# STM32L412xx register map
File version: 1.0
Registers are 32-bit, read-write, reset 0x0 unless marked. A register's access mark holds for its fields unless they carry their own. Offsets are from the block's base; [hi:lo] are bit positions; {n}, {i} and the like mark numbered series; 'fields as' and 'values as' point back to an identical list.

## FIREWALL
Base 0x40011C00
0x00 CSSA — Code Segment Start Address register
0x04 CSL — Code Segment Length register
0x08 NVDSSA — NON volatile data Segment Start Address register
0x0C NVDSL — NON volatile data Segment Length register
0x10 VDSSA — Volatile data Segment Start Address register
0x14 VDSL — Volatile data Segment Length register
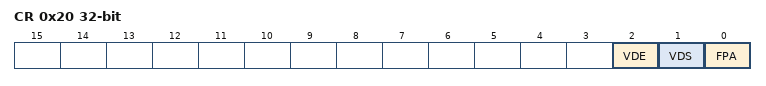
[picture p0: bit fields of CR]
0x20 CR — Configuration register
  [2] VDE — Volatile Data Execution
  [1] VDS — Volatile Data Sharing
  [0] FPA — Firewall Pre Arm

## DMA1
Base 0x40020000
Same registers: DMA2 0x40020400
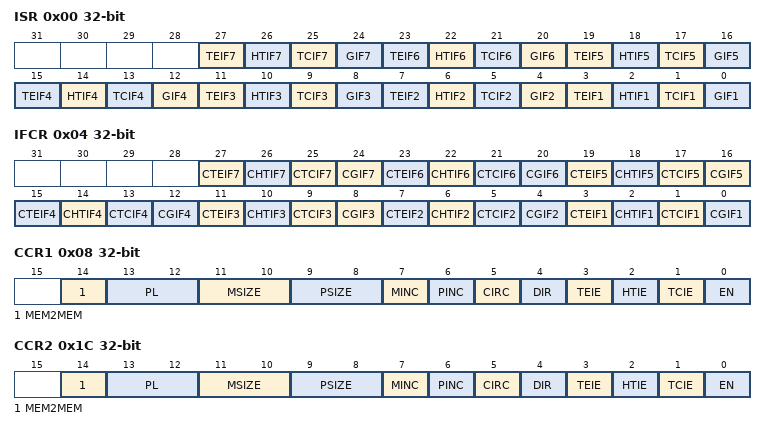
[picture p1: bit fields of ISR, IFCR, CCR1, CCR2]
0x00 ISR — DMA interrupt status register
  [4n-1] TEIF{n} (n=1..7) — Channel {n} Transfer Error flag
  [4n-2] HTIF{n} (n=1..7) — Channel {n} Half Transfer flag
  [4n-3] TCIF{n} (n=1..7) — Channel {n} Transfer Complete flag
  [4n-4] GIF{n} (n=1..7) — Channel {n} Global interrupt flag
0x04 IFCR — DMA interrupt flag clear register
  [4n-1] CTEIF{n} (n=1..7) — Channel {n} Transfer Error clear
  [4n-2] CHTIF{n} (n=1..7) — Channel {n} Half Transfer clear
  [4n-3] CTCIF{n} (n=1..7) — Channel {n} Transfer Complete clear
  [4n-4] CGIF{n} (n=2..7) — Channel {n} Global interrupt clear
  [0] CGIF1 — Channel 1 Global interrupt clearr
0x08 CCR1 — DMA channel x configuration register
  [14] MEM2MEM — Memory to memory mode
  [13:12] PL — PL[1:0] bits(Channel Priority level)
  [11:10] MSIZE — MSIZE[1:0] bits (Memory size)
  [9:8] PSIZE — PSIZE[1:0] bits (Peripheral size)
  [7] MINC — Memory increment mode
  [6] PINC — Peripheral increment mode
  [5] CIRC — Circular mode
  [4] DIR — Data transfer direction
  [3] TEIE — Transfer error interrupt enable
  [2] HTIE — Half Transfer interrupt enable
  [1] TCIE — Transfer complete interrupt enable
  [0] EN — Channel enable
0x0C CNDTR1 — DMA channel x number of data register
  [15:0] NDT — Number of data to Transfer
0x10 CPAR1 — DMA channel x peripheral address register
  [31:0] PA — Peripheral Address
{0x0+0x14*i} CMAR{i} (i=1..7) — DMA channel x memory address register
  [31:0] MA — Memory Address
0x1C CCR2 — DMA channel x configuration register
  fields as CCR1
0x20 CNDTR2 — DMA channel x number of data register
  [15:0] NDT — Number of data to Transfer
0x24 CPAR2 — DMA channel x peripheral address register
  [31:0] PA — Peripheral Address
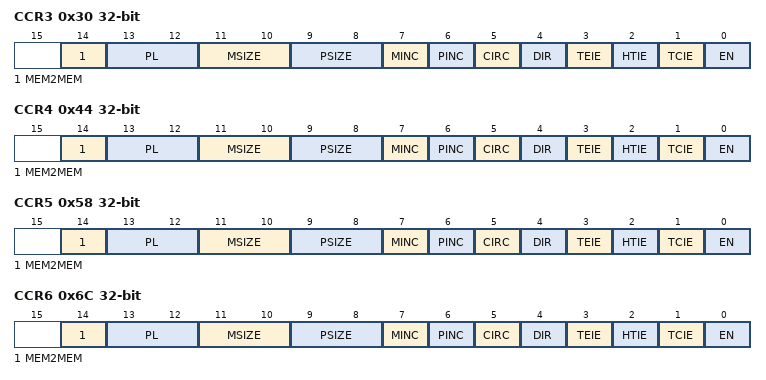
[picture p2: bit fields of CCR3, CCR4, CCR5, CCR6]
0x30 CCR3 — DMA channel x configuration register
  fields as CCR1
0x34 CNDTR3 — DMA channel x number of data register
  [15:0] NDT — Number of data to Transfer
0x38 CPAR3 — DMA channel x peripheral address register
  [31:0] PA — Peripheral Address
0x44 CCR4 — DMA channel x configuration register
  fields as CCR1
0x48 CNDTR4 — DMA channel x number of data register
  [15:0] NDT — Number of data to Transfer
0x4C CPAR4 — DMA channel x peripheral address register
  [31:0] PA — Peripheral Address
0x58 CCR5 — DMA channel x configuration register
  fields as CCR1
0x5C CNDTR5 — DMA channel x number of data register
  [15:0] NDT — Number of data to Transfer
0x60 CPAR5 — DMA channel x peripheral address register
  [31:0] PA — Peripheral Address
0x6C CCR6 — DMA channel x configuration register
  fields as CCR1
0x70 CNDTR6 — DMA channel x number of data register
  [15:0] NDT — Number of data to Transfer
0x74 CPAR6 — DMA channel x peripheral address register
  [31:0] PA — Peripheral Address
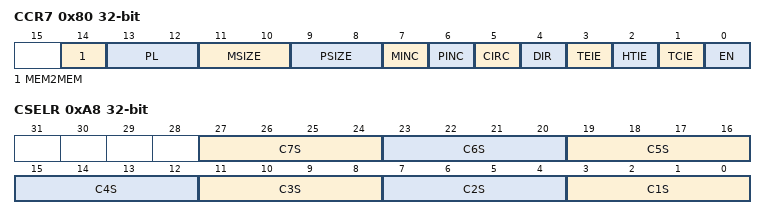
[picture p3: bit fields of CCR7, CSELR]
0x80 CCR7 — DMA channel x configuration register
  fields as CCR1
0x84 CNDTR7 — DMA channel x number of data register
  [15:0] NDT — Number of data to Transfer
0x88 CPAR7 — DMA channel x peripheral address register
  [31:0] PA — Peripheral Address
0xA8 CSELR — DMA channel selection register
  [4n-1:4n-4] C{n}S (n=1..7) — Channel {n} Selection

## FLASH — FLASH Registers
Base 0x40022000
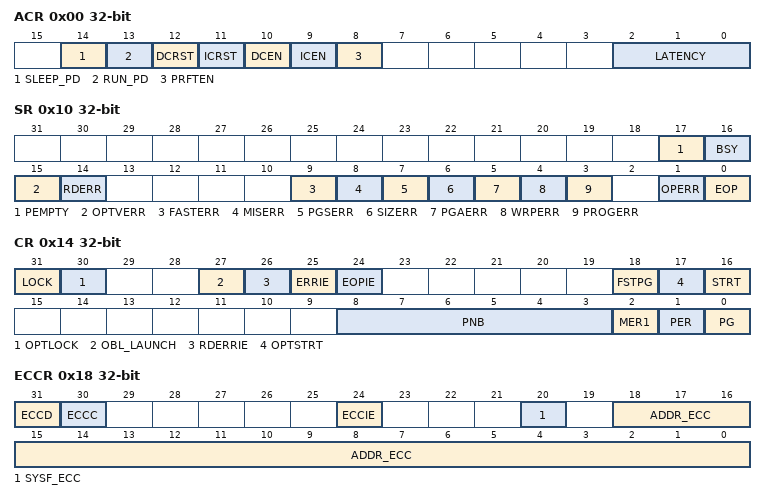
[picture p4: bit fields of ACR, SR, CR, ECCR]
0x00 ACR — FLASH access control register
  [14] SLEEP_PD — Flash power down mode during sleep
  [13] RUN_PD — Flash power down mode during run
  [12] DCRST
  [11] ICRST
  [10] DCEN
  [9] ICEN
  [8] PRFTEN
  [2:0] LATENCY
    0=FLASH Zero wait state; 1=FLASH One wait state; 2=FLASH Two wait states; 3=FLASH Three wait states; 4=FLASH Four wait states
0x04 PDKEYR — FLASH power down key register
0x08 KEYR — FLASH key register
0x0C OPTKEYR — FLASH option key register
0x10 SR — FLASH status register
  [17] PEMPTY, [16] BSY, [15] OPTVERR, [14] RDERR, [9] FASTERR, [8] MISERR, [7] PGSERR, [6] SIZERR, [5] PGAERR, [4] WRPERR, [3] PROGERR, [1] OPERR, [0] EOP
0x14 CR — FLASH control register
  [31] LOCK, [30] OPTLOCK, [27] OBL_LAUNCH, [26] RDERRIE, [25] ERRIE, [24] EOPIE, [18] FSTPG, [17] OPTSTRT, [16] STRT, [8:3] PNB, [2] MER1, [1] PER, [0] PG
0x18 ECCR — FLASH ECC register
  [31] ECCD, [30] ECCC, [24] ECCIE, [20] SYSF_ECC, [18:0] ADDR_ECC
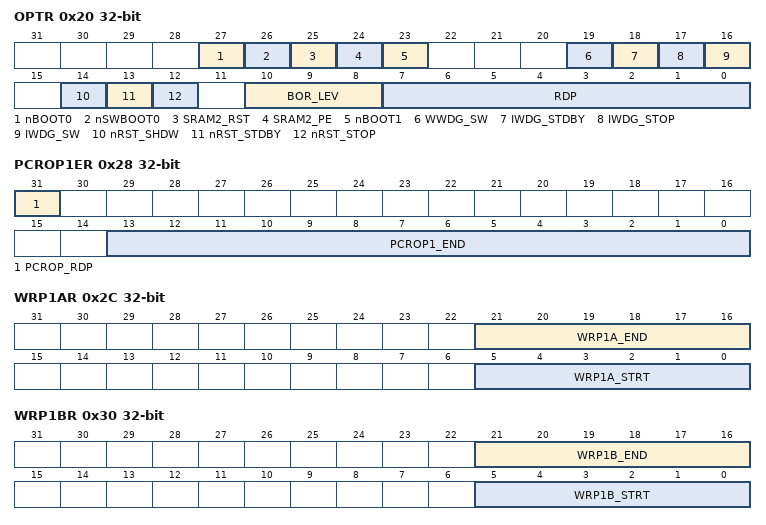
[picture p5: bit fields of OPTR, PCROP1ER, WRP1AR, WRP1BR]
0x20 OPTR — FLASH option register
  [27] nBOOT0, [26] nSWBOOT0, [25] SRAM2_RST, [24] SRAM2_PE, [23] nBOOT1, [19] WWDG_SW, [18] IWDG_STDBY, [17] IWDG_STOP, [16] IWDG_SW, [14] nRST_SHDW, [13] nRST_STDBY, [12] nRST_STOP, [10:8] BOR_LEV, [7:0] RDP
0x24 PCROP1SR — FLASH bank1 PCROP start address register
  [13:0] PCROP1_STRT
0x28 PCROP1ER — FLASH bank1 PCROP end address register
  [31] PCROP_RDP, [13:0] PCROP1_END
0x2C WRP1AR — FLASH bank1 WRP area A address register
  [21:16] WRP1A_END, [5:0] WRP1A_STRT
0x30 WRP1BR — FLASH bank1 WRP area B address register
  [21:16] WRP1B_END, [5:0] WRP1B_STRT
